# Sis08FirstSlice register map
File version: 1.0
SOS-09-B generated CMSIS-SVD description for Sis08FirstSlice
Registers are 32-bit, read-write, reset 0x0 unless marked. A register's access mark holds for its fields unless they carry their own. Offsets are from the block's base; lines under a group give offsets from that group; [hi:lo] are bit positions; {n}, {i} and the like mark numbered series; 'fields as' and 'values as' point back to an identical list; <NAME> marks a mode.

## Memory map
0x40000000 Sis08FirstSlice size 0x14 — SOS-09-B channel block for Sis08FirstSlice

## Interrupts
0 fifo_irq (Sis08FirstSlice) — SOS-09-B placeholder vector for channel 'fifo_status'
1 mailbox_irq (Sis08FirstSlice) — SOS-09-B placeholder vector for channel 'mailbox_notify'

## Sis08FirstSlice — SOS-09-B channel block for Sis08FirstSlice
Base 0x40000000
0x00 fifo_data — SOS-09-B channel 'fifo_data' (kind=queue, dir=hw↔sw)
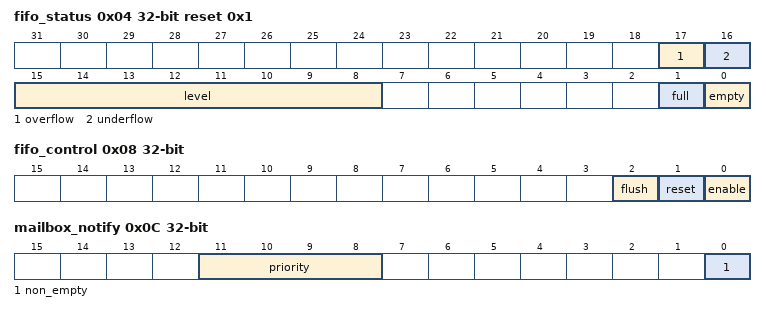
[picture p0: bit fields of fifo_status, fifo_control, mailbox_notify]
0x04 fifo_status ro reset 0x1 read-clears — SOS-09-B channel 'fifo_status' (kind=status, dir=hw→sw)
  [17] overflow read-clears — bit-field 'overflow' (access=RO)
  [16] underflow read-clears — bit-field 'underflow' (access=RO)
  [15:8] level — bit-field 'level' (access=RO)
  [1] full — bit-field 'full' (access=RO)
  [0] empty — bit-field 'empty' (access=RO)
0x08 fifo_control wo — SOS-09-B channel 'fifo_control' (kind=command, dir=sw→hw)
  [2] flush — bit-field 'flush' (access=WO)
  [1] reset — bit-field 'reset' (access=WO)
  [0] enable — bit-field 'enable' (access=WO)
0x0C mailbox_notify ro read-clears — SOS-09-B channel 'mailbox_notify' (kind=status, dir=hw→sw)
  [11:8] priority — bit-field 'priority' (access=RO)
  [0] non_empty read-clears — bit-field 'non_empty' (access=RO)
0x10 credit_budget — SOS-09-B channel 'credit_budget' (kind=shared, dir=hw↔sw)
